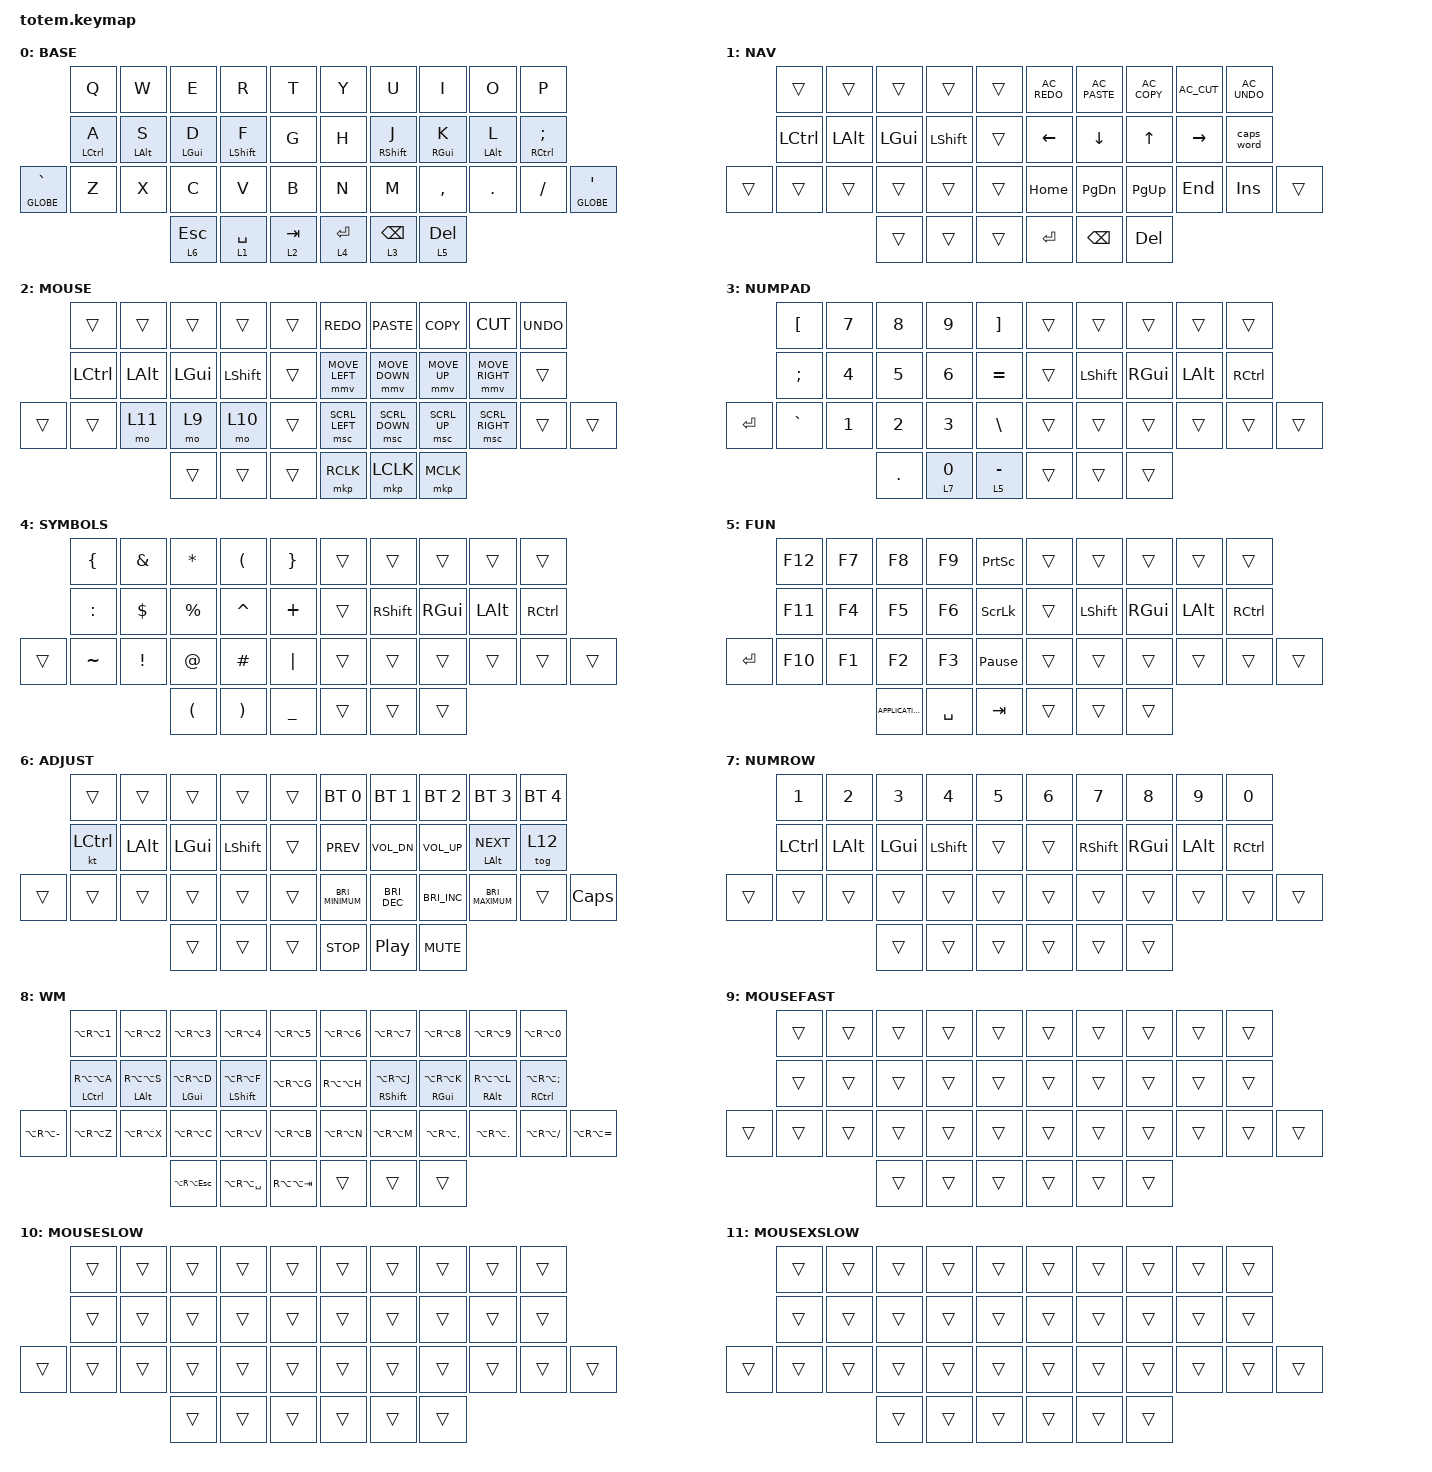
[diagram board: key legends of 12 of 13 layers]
//
//                                                        ▀▀▀▀▀     ▀▀▀▀▀          ▀▀█▀▀
//                                                        ▄▀▀▀▄  ▄  ▄▀▀▀▄  ▄  ▄▀▀▀▄  █  ▄▀▀▀▄
//                                                        █   █  █  █   █  █  █   █  █  █   █
//                                                         ▀▀▀   █   ▀▀▀   █   ▀▀▀   ▀   ▀▀▀
//                                                               █      ▄▄▄█▄▄▄    █   █  
//                                                               ▀      █  █  █     █▄█
//                                                             ▀▀▀▀▀    █  █  █      ▀
//                                                                      ▀  ▀  ▀
//
// ▄▄▄▄▄▄▄▄▄▄▄▄▄▄▄▄▄▄▄▄▄▄▄▄▄▄▄▄▄▄▄▄▄▄▄▄▄▄▄▄▄▄▄▄▄▄▄▄▄▄▄▄▄▄▄▄▄▄▄▄▄▄▄▄▄▄▄▄▄▄▄▄▄▄▄▄▄▄▄▄▄▄▄▄▄▄▄▄▄▄▄▄▄▄▄▄▄▄▄▄▄▄▄▄▄▄▄▄▄▄▄▄▄▄▄▄▄▄▄▄▄▄▄▄▄▄▄▄▄▄▄▄▄▄▄▄▄▄▄▄▄▄▄▄▄▄▄▄▄

#include "zmk-helpers/helper.h"

#define TAPPING_TERM 180
#define TAPPING_TERM_FAST 150
#define HM_TAPPING_TERM 180
#define HM_TAPPING_TERM_FAST 150
#define HM_PRIOR_IDLE 120
#define COMBO_TERM_FAST 35
#define COMBO_TERM_SLOW 40
#define COMBO_PRIOR_IDLE 80
#define ZMK_POINTING_DEFAULT_MOVE_VAL 900  // default: 600
#define ZMK_POINTING_DEFAULT_SCRL_VAL 20   // default: 10 - same as move for smooth scroll
#define BASE 0
#define NAV 1
#define MOUSE 2
#define NUMPAD 3
#define SYMBOLS 4
#define FUN 5
#define ADJUST 6
#define NUMROW 7
#define WM 8
#define MOUSEFAST 9
#define MOUSESLOW 10
#define MOUSEXSLOW 11

/* use helper macros to define left and right hand keys */

#include "zmk-helpers/key-labels/totem.h"                                   // key-position labels
#include <input/processors.dtsi>
#include <behaviors.dtsi>
#include <dt-bindings/zmk/bt.h>
#include <dt-bindings/zmk/keys.h>
#include <dt-bindings/zmk/pointing.h>

#define KEYS_L LT0 LT1 LT2 LT3 LT4 LM0 LM1 LM2 LM3 LM4 LB0 LB1 LB2 LB3 LB4  // left-hand keys
#define KEYS_R RT0 RT1 RT2 RT3 RT4 RM0 RM1 RM2 RM3 RM4 RB0 RB1 RB2 RB3 RB4  // right-hand keys
#define KEYS_T LH2 LH1 LH0 RH0 RH1 RH2                                      // thumb keys

&mmv_input_listener {
    set_mouse_fast {
        layers = <MOUSEFAST>;
        input-processors = <&zip_xy_scaler 2 1>;
    };
};

&mmv_input_listener {
    set_mouse_slow {
        layers = <MOUSESLOW>;
        input-processors = <&zip_xy_scaler 1 2>;
    };
};

&mmv_input_listener {
    set_mouse_extra_slow {
        layers = <MOUSEXSLOW>;
        input-processors = <&zip_xy_scaler 1 4>;
    };
};

&lt {
    tapping-term-ms = <TAPPING_TERM>;
    quick-tap-ms = <TAPPING_TERM_FAST>;
};

&mt {
    tapping-term-ms = <TAPPING_TERM>;
    quick-tap-ms = <TAPPING_TERM_FAST>;
};

/ {
    combos {
        compatible = "zmk,combos";

        //INFO: Brackets and braces
        //INFO: System commands
        //INFO: Edit commands
        //INFO: Special characters

        combo_at {
            timeout-ms = <COMBO_TERM_FAST>;
            require-prior-idle-ms = <COMBO_PRIOR_IDLE>;
            bindings = <&kp AT_SIGN>;
            key-positions = <1 11>;
        };

        combo_pound {
            timeout-ms = <COMBO_TERM_FAST>;
            require-prior-idle-ms = <COMBO_PRIOR_IDLE>;
            bindings = <&kp POUND>;
            key-positions = <2 12>;
        };

        combo_dollar {
            timeout-ms = <COMBO_TERM_FAST>;
            require-prior-idle-ms = <COMBO_PRIOR_IDLE>;
            bindings = <&kp DOLLAR>;
            key-positions = <3 13>;
        };

        combo_percent {
            timeout-ms = <COMBO_TERM_FAST>;
            require-prior-idle-ms = <COMBO_PRIOR_IDLE>;
            bindings = <&kp PERCENT>;
            key-positions = <4 14>;
        };

        combo_caret {
            timeout-ms = <COMBO_TERM_FAST>;
            require-prior-idle-ms = <COMBO_PRIOR_IDLE>;
            bindings = <&kp CARET>;
            key-positions = <5 15>;
        };

        combo_plus {
            timeout-ms = <COMBO_TERM_FAST>;
            require-prior-idle-ms = <COMBO_PRIOR_IDLE>;
            bindings = <&kp PLUS>;
            key-positions = <6 16>;
        };

        combo_star {
            timeout-ms = <COMBO_TERM_FAST>;
            require-prior-idle-ms = <COMBO_PRIOR_IDLE>;
            bindings = <&kp STAR>;
            key-positions = <7 17>;
        };

        combo_ampersand {
            timeout-ms = <COMBO_TERM_FAST>;
            require-prior-idle-ms = <COMBO_PRIOR_IDLE>;
            bindings = <&kp AMPERSAND>;
            key-positions = <8 18>;
        };

        combo_grave {
            timeout-ms = <COMBO_TERM_FAST>;
            require-prior-idle-ms = <COMBO_PRIOR_IDLE>;
            bindings = <&kp GRAVE>;
            key-positions = <11 22>;
        };

        combo_backslash {
            timeout-ms = <COMBO_TERM_FAST>;
            require-prior-idle-ms = <COMBO_PRIOR_IDLE>;
            bindings = <&kp BSLH>;
            key-positions = <12 23>;
        };

        combo_equal {
            timeout-ms = <COMBO_TERM_FAST>;
            require-prior-idle-ms = <COMBO_PRIOR_IDLE>;
            bindings = <&kp EQUAL>;
            key-positions = <13 24>;
        };

        combo_tilde {
            timeout-ms = <COMBO_TERM_FAST>;
            require-prior-idle-ms = <COMBO_PRIOR_IDLE>;
            bindings = <&kp TILDE>;
            key-positions = <14 25>;
        };

        combo_underscore {
            timeout-ms = <COMBO_TERM_FAST>;
            require-prior-idle-ms = <COMBO_PRIOR_IDLE>;
            bindings = <&kp UNDERSCORE>;
            key-positions = <15 26>;
        };

        combo_minus {
            timeout-ms = <COMBO_TERM_FAST>;
            require-prior-idle-ms = <COMBO_PRIOR_IDLE>;
            bindings = <&kp MINUS>;
            key-positions = <16 27>;
        };

        combo_slash {
            timeout-ms = <COMBO_TERM_FAST>;
            require-prior-idle-ms = <COMBO_PRIOR_IDLE>;
            bindings = <&kp FSLH>;
            key-positions = <28 17>;
        };

        combo_pipe {
            timeout-ms = <COMBO_TERM_FAST>;
            require-prior-idle-ms = <COMBO_PRIOR_IDLE>;
            bindings = <&kp PIPE>;
            key-positions = <18 29>;
        };

        combo_esc {
            timeout-ms = <COMBO_TERM_FAST>;
            require-prior-idle-ms = <COMBO_PRIOR_IDLE>;
            bindings = <&kp ESCAPE>;
            key-positions = <1 2>;
        };

        combo_mse {
            timeout-ms = <COMBO_TERM_FAST>;
            require-prior-idle-ms = <COMBO_PRIOR_IDLE>;
            bindings = <&mo 2>;
            key-positions = <2 3>;
        };

        combo_tab {
            timeout-ms = <COMBO_TERM_FAST>;
            require-prior-idle-ms = <COMBO_PRIOR_IDLE>;
            bindings = <&kp TAB>;
            key-positions = <11 12>;
        };

        combo_undo {
            timeout-ms = <COMBO_TERM_FAST>;
            require-prior-idle-ms = <COMBO_PRIOR_IDLE>;
            bindings = <&kp K_UNDO>;
            key-positions = <21 22>;
        };

        combo_redo {
            timeout-ms = <COMBO_TERM_FAST>;
            require-prior-idle-ms = <COMBO_PRIOR_IDLE>;
            bindings = <&kp K_REDO>;
            key-positions = <24 25>;
        };

        combo_copy {
            timeout-ms = <COMBO_TERM_FAST>;
            require-prior-idle-ms = <COMBO_PRIOR_IDLE>;
            bindings = <&kp K_COPY>;
            key-positions = <22 23>;
        };

        combo_paste {
            timeout-ms = <COMBO_TERM_FAST>;
            require-prior-idle-ms = <COMBO_PRIOR_IDLE>;
            bindings = <&kp K_PASTE>;
            key-positions = <23 24>;
        };

        combo_backspace {
            timeout-ms = <COMBO_TERM_FAST>;
            require-prior-idle-ms = <COMBO_PRIOR_IDLE>;
            bindings = <&kp BACKSPACE>;
            key-positions = <6 7>;
        };

        combo_delete {
            timeout-ms = <COMBO_TERM_FAST>;
            require-prior-idle-ms = <COMBO_PRIOR_IDLE>;
            bindings = <&kp DELETE>;
            key-positions = <7 8>;
        };

        combo_l_par {
            timeout-ms = <COMBO_TERM_FAST>;
            require-prior-idle-ms = <COMBO_PRIOR_IDLE>;
            bindings = <&kp LPAR>;
            key-positions = <16 17>;
        };

        combo_r_par {
            timeout-ms = <COMBO_TERM_FAST>;
            require-prior-idle-ms = <COMBO_PRIOR_IDLE>;
            bindings = <&kp RPAR>;
            key-positions = <17 18>;
        };

        combo_l_bracket {
            timeout-ms = <COMBO_TERM_FAST>;
            require-prior-idle-ms = <COMBO_PRIOR_IDLE>;
            bindings = <&kp LBKT>;
            key-positions = <27 28>;
        };

        combo_r_bracket {
            timeout-ms = <COMBO_TERM_FAST>;
            require-prior-idle-ms = <COMBO_PRIOR_IDLE>;
            bindings = <&kp RBKT>;
            key-positions = <28 29>;
        };

        combo_caps_word {
            timeout-ms = <COMBO_TERM_FAST>;
            require-prior-idle-ms = <COMBO_PRIOR_IDLE>;
            bindings = <&caps_word>;
            key-positions = <16 13>;
        };

        bt_clr {
            bindings = <&bt BT_CLR>;
            key-positions = <20 31>;
            layers = <6>;
        };
    };

    behaviors {
        hm_l: homerow_mods_left {
            compatible = "zmk,behavior-hold-tap";
            #binding-cells = <2>;
            bindings = <&kp>, <&kp>;

            flavor = "balanced";
            tapping-term-ms = <HM_TAPPING_TERM>;
            quick-tap-ms = <HM_TAPPING_TERM_FAST>;
            require-prior-idle-ms = <HM_PRIOR_IDLE>;
            hold-trigger-key-positions = <KEYS_R KEYS_T>;
            hold-trigger-on-release;
        };

        hm_r: homerow_mods_right {
            compatible = "zmk,behavior-hold-tap";
            #binding-cells = <2>;
            bindings = <&kp>, <&kp>;

            flavor = "balanced";
            tapping-term-ms = <HM_TAPPING_TERM>;
            quick-tap-ms = <HM_TAPPING_TERM_FAST>;
            require-prior-idle-ms = <HM_PRIOR_IDLE>;
            hold-trigger-key-positions = <KEYS_L KEYS_T>;
            hold-trigger-on-release;
        };
    };

    keymap {
        compatible = "zmk,keymap";

        base {
            display-name = "BASE";
            bindings = <
                 &kp Q          &kp W         &kp E         &kp R          &kp T        &kp Y        &kp U            &kp I         &kp O         &kp P
                 &hm_l LCTRL A  &hm_l LALT S  &hm_l LGUI D  &hm_l LSHFT F  &kp G        &kp H        &hm_r RSHFT J    &hm_r RGUI K  &hm_r LALT L  &hm_r RCTRL SEMI
&mt GLOBE GRAVE  &kp Z          &kp X         &kp C         &kp V          &kp B        &kp N        &kp M            &kp COMMA     &kp DOT       &kp SLASH         &mt GLOBE SQT
                                              &lt 6 ESCAPE  &lt 1 SPACE    &lt 2 TAB    &lt 4 ENTER  &lt 3 BACKSPACE  &lt 5 DELETE
            >;
        };

        nav {
            bindings = <
        &trans     &trans    &trans    &trans     &trans    &kp C_AC_REDO  &kp C_AC_PASTE  &kp C_AC_COPY  &kp C_AC_CUT  &kp C_AC_UNDO
        &kp LCTRL  &kp LALT  &kp LGUI  &kp LSHFT  &trans    &kp LEFT       &kp DOWN        &kp UP         &kp RIGHT     &caps_word
&trans  &trans     &trans    &trans    &trans     &trans    &kp HOME       &kp PAGE_DOWN   &kp PAGE_UP    &kp END       &kp INSERT     &trans
                             &trans    &trans     &trans    &kp ENTER      &kp BACKSPACE   &kp DELETE
            >;

            label = "NAV";
        };

        mouse {
            bindings = <
        &trans     &trans    &trans    &trans     &trans    &kp K_REDO      &kp K_PASTE     &kp K_COPY    &kp K_CUT        &kp K_UNDO
        &kp LCTRL  &kp LALT  &kp LGUI  &kp LSHFT  &trans    &mmv MOVE_LEFT  &mmv MOVE_DOWN  &mmv MOVE_UP  &mmv MOVE_RIGHT  &trans
&trans  &trans     &mo 11    &mo 9     &mo 10     &trans    &msc SCRL_LEFT  &msc SCRL_DOWN  &msc SCRL_UP  &msc SCRL_RIGHT  &trans      &trans
                             &trans    &trans     &trans    &mkp RCLK       &mkp LCLK       &mkp MCLK
            >;

            label = "MOUSE";
        };

        numpad {
            display-name = "NUMPAD";
            bindings = <
           &kp LEFT_BRACKET  &kp N7  &kp N8      &kp N9          &kp RIGHT_BRACKET    &trans  &trans      &trans    &trans    &trans
           &kp SEMICOLON     &kp N4  &kp N5      &kp N6          &kp EQUAL            &trans  &kp LSHIFT  &kp RGUI  &kp LALT  &kp RCTRL
&kp ENTER  &kp GRAVE         &kp N1  &kp N2      &kp N3          &kp BACKSLASH        &trans  &trans      &trans    &trans    &trans     &trans
                                     &kp PERIOD  &lt 7 NUMBER_0  &lt 5 MINUS          &trans  &trans      &trans
            >;
        };

        symbols {
            bindings = <
        &kp LEFT_BRACE  &kp AMPERSAND    &kp ASTERISK          &kp LEFT_PARENTHESIS   &kp RIGHT_BRACE    &trans  &trans     &trans    &trans    &trans
        &kp COLON       &kp DOLLAR       &kp PERCENT           &kp CARET              &kp PLUS           &trans  &kp RSHFT  &kp RGUI  &kp LALT  &kp RCTRL
&trans  &kp TILDE       &kp EXCLAMATION  &kp AT                &kp HASH               &kp PIPE           &trans  &trans     &trans    &trans    &trans     &trans
                                         &kp LEFT_PARENTHESIS  &kp RIGHT_PARENTHESIS  &kp UNDERSCORE     &trans  &trans     &trans
            >;

            label = "SYMBOLS";
        };

        fun {
            display-name = "FUN";
            bindings = <
           &kp F12  &kp F7  &kp F8             &kp F9     &kp PRINTSCREEN    &trans  &trans      &trans    &trans    &trans
           &kp F11  &kp F4  &kp F5             &kp F6     &kp SCROLLLOCK     &trans  &kp LSHIFT  &kp RGUI  &kp LALT  &kp RCTRL
&kp ENTER  &kp F10  &kp F1  &kp F2             &kp F3     &kp PAUSE_BREAK    &trans  &trans      &trans    &trans    &trans     &trans
                            &kp K_APPLICATION  &kp SPACE  &kp TAB            &trans  &trans      &trans
            >;
        };

        adjust {
            bindings = <
        &trans     &trans    &trans    &trans     &trans    &bt BT_SEL 0              &bt BT_SEL 1          &bt BT_SEL 2          &bt BT_SEL 3              &bt BT_SEL 4
        &kt LCTRL  &kp LALT  &kp LGUI  &kp LSHFT  &trans    &kp C_PREV                &kp C_VOL_DN          &kp C_VOL_UP          &hm_r LALT C_NEXT         &tog 12
&trans  &trans     &trans    &trans    &trans     &trans    &kp C_BRIGHTNESS_MINIMUM  &kp C_BRIGHTNESS_DEC  &kp C_BRIGHTNESS_INC  &kp C_BRIGHTNESS_MAXIMUM  &trans        &kp CAPSLOCK
                             &trans    &trans     &trans    &kp C_STOP                &kp C_PLAY_PAUSE      &kp K_MUTE
            >;

            label = "ADJUST";
        };

        numrow {
            bindings = <
        &kp N1     &kp N2    &kp N3    &kp N4     &kp N5    &kp N6  &kp N7     &kp N8    &kp N9    &kp N0
        &kp LCTRL  &kp LALT  &kp LGUI  &kp LSHFT  &trans    &trans  &kp RSHFT  &kp RGUI  &kp LALT  &kp RCTRL
&trans  &trans     &trans    &trans    &trans     &trans    &trans  &trans     &trans    &trans    &trans     &trans
                             &trans    &trans     &trans    &trans  &trans     &trans
            >;

            label = "NUMROW";
        };

        wm {
            bindings = <
                   &kp LA(RA(NUMBER_1))   &kp LA(RA(NUMBER_2))  &kp LA(RA(NUMBER_3))  &kp LA(RA(NUMBER_4))   &kp LA(RA(NUMBER_5))    &kp LA(RA(NUMBER_6))  &kp LA(RA(NUMBER_7))    &kp LA(RA(N8))        &kp LA(RA(N9))        &kp LA(RA(N0))
                   &hm_l LCTRL RA(LA(A))  &hm_l LALT RA(LA(S))  &hm_l LGUI LA(RA(D))  &hm_l LSHFT LA(RA(F))  &kp LA(RA(G))           &kp RA(LA(H))         &hm_r RSHIFT LA(RA(J))  &hm_r RGUI LA(RA(K))  &hm_r RALT RA(LA(L))  &hm_r RCTRL LA(RA(SEMICOLON))
&kp LA(RA(MINUS))  &kp LA(RA(Z))          &kp LA(RA(X))         &kp LA(RA(C))         &kp LA(RA(V))          &kp LA(RA(B))           &kp LA(RA(N))         &kp LA(RA(M))           &kp LA(RA(COMMA))     &kp LA(RA(PERIOD))    &kp LA(RA(SLASH))              &kp LA(RA(EQUAL))
                                                                &kp LA(RA(ESCAPE))    &kp LA(RA(SPACE))      &kp RA(LA(TAB))         &trans                &trans                  &trans
            >;

            label = "WM";
        };

        mousefast {
            bindings = <
        &trans  &trans  &trans  &trans  &trans    &trans  &trans  &trans  &trans  &trans
        &trans  &trans  &trans  &trans  &trans    &trans  &trans  &trans  &trans  &trans
&trans  &trans  &trans  &trans  &trans  &trans    &trans  &trans  &trans  &trans  &trans  &trans
                        &trans  &trans  &trans    &trans  &trans  &trans
            >;

            label = "MOUSEFAST";
        };

        mouseslow {
            bindings = <
        &trans  &trans  &trans  &trans  &trans    &trans  &trans  &trans  &trans  &trans
        &trans  &trans  &trans  &trans  &trans    &trans  &trans  &trans  &trans  &trans
&trans  &trans  &trans  &trans  &trans  &trans    &trans  &trans  &trans  &trans  &trans  &trans
                        &trans  &trans  &trans    &trans  &trans  &trans
            >;

            label = "MOUSESLOW";
        };

        mousexslow {
            bindings = <
        &trans  &trans  &trans  &trans  &trans    &trans  &trans  &trans  &trans  &trans
        &trans  &trans  &trans  &trans  &trans    &trans  &trans  &trans  &trans  &trans
&trans  &trans  &trans  &trans  &trans  &trans    &trans  &trans  &trans  &trans  &trans  &trans
                        &trans  &trans  &trans    &trans  &trans  &trans
            >;

            label = "MOUSEXSLOW";
        };

        gaming {
            bindings = <
              &kp Q  &kp W  &kp E      &kp R      &kp T         &kp Y      &kp U     &kp I      &kp O       &kp P
              &kp A  &kp S  &kp D      &kp F      &kp G         &kp H      &kp J     &kp K      &kp L       &kp SEMICOLON
&lt 6 ESCAPE  &kp Z  &kp X  &kp C      &kp V      &kp B         &kp N      &kp M     &kp COMMA  &kp PERIOD  &kp SLASH      &kp SQT
                            &kp LCTRL  &kp SPACE  &kp LSHIFT    &kp ENTER  &kp LALT  &kp LGUI
            >;

            label = "gaming";
        };
    };
};
